# PRM_DEVICE register map
Vendor: Texas Instruments
Peripheral module from a debugger description file (folder am437x).
Registers are 32-bit, access per field, no defined reset value unless marked. A register's access mark holds for its fields unless they carry their own. Offsets are as the file gives them; lines under a group give offsets from that group; [hi:lo] are bit positions; {n}, {i} and the like mark numbered series; 'fields as' and 'values as' point back to an identical list; <NAME> marks a mode.

## PRM_DEVICE
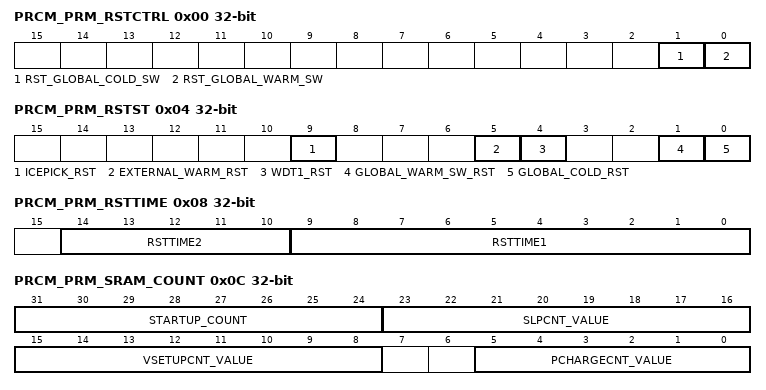
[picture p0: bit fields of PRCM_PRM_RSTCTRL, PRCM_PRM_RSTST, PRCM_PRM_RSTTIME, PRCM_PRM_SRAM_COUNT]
0x00 PRCM_PRM_RSTCTRL — Global software cold and warm reset control. This register is auto-cleared. Only write 1 is possible. A read returns 0 only.
  [1] RST_GLOBAL_COLD_SW rw — Global COLD software reset control. [[br]]This bit is reset only upon a global cold source of reset.
    1=en_2_0x1 (0X1 : Asserts a global COLD software reset. The software must ensure the SDRAM is properly put in sef-refresh mode before applying this reset.); 0=en_1_0x0 (0X0 : Global COLD software reset is cleared.)
  [0] RST_GLOBAL_WARM_SW rw — Global WARM software reset control. [[br]]This bit is reset upon any global source of reset (warm and cold).
    1=en_2_0x1 (0X1 : Asserts a global warm software reset.); 0=en_1_0x0 (0X0 : Global warm software reset is cleared.)
0x04 PRCM_PRM_RSTST — This register logs the global reset sources. Each bit is set upon release of the domain reset signal. Must be cleared by software. [warm reset insensitive]
  [9] ICEPICK_RST rw — IcePick reset event. [[br]]This is a source of global warm reset initiated by the emulation. [[br]][warm reset insensitive]
    1=en_2_0x1 (0X1 : IcePick reset has occurred.); 0=en_1_0x0 (0X0 : No ICEPICK reset.)
  [5] EXTERNAL_WARM_RST rw — External warm reset event [warm reset insensitive]
    1=en_2_0x1 (0X1 : Global external warm reset has occurred.); 0=en_1_0x0 (0X0 : No global warm reset.)
  [4] WDT1_RST rw — Watchdog1 timer reset event. [[br]]This is a source of global WARM reset. [[br]][warm reset insensitive]
    1=en_2_0x1 (0X1 : watchdog reset has occurred.); 0=en_1_0x0 (0X0 : No watchdog reset.)
  [1] GLOBAL_WARM_SW_RST rw — Global warm software reset event [warm reset insensitive]
    1=en_2_0x1 (0X1 : Global warm SW reset has occurred.); 0=en_1_0x0 (0X0 : No global warm SW reset)
  [0] GLOBAL_COLD_RST rw — Power-on (cold) reset event [warm reset insensitive]
    1=en_2_0x1 (0X1 : Power-on reset has occurred.); 0=en_1_0x0 (0X0 : No power-on reset.)
0x08 PRCM_PRM_RSTTIME — Reset duration control. [warm reset insensitive]
  [14:10] RSTTIME2 rw — (Power domain) reset duration 2 (number of RM.SYSCLK clock cycles)
  [9:0] RSTTIME1 rw — (Global) reset duration 1 (number of SYS_CLK clock cycles)
0x0C PRCM_PRM_SRAM_COUNT — Common setup for SRAM LDO transition counters. Applies to all voltage domains. [warm reset insensitive]
  [31:24] STARTUP_COUNT rw — Determines the start-up duration of SRAM and ABB LDO. [[br]]The duration is computed as 16 x NbCycles of system clock cycles. [[br]]Target is 50us.
  [23:16] SLPCNT_VALUE rw — Delay between retention/off assertion of last SRAM bank and SRAMALLRET signal to LDO is driven high. [[br]]Counting on system clock. [[br]]Target is 2us.
  [15:8] VSETUPCNT_VALUE rw — SRAM LDO rampup time from retention to active mode. [[br]]The duration is computed as 8 x NbCycles of system clock cycles. [[br]]Target is 30us.
  [5:0] PCHARGECNT_VALUE rw — Delay between de-assertion of standby_rta_ret_on and standby_rta_ret_good. [[br]]Counting on system clock. [[br]]Target is 600ns.
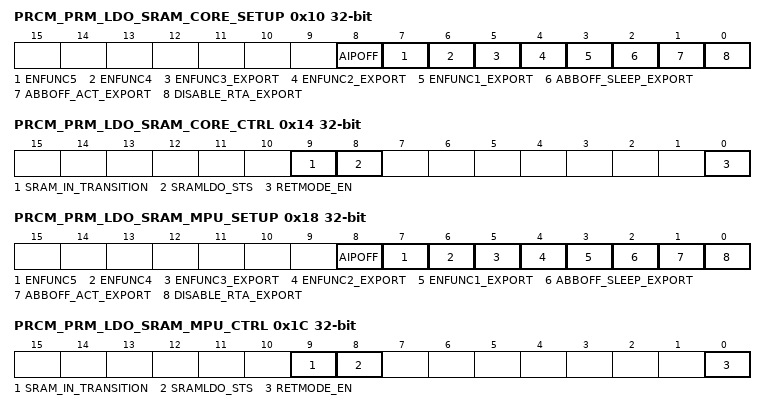
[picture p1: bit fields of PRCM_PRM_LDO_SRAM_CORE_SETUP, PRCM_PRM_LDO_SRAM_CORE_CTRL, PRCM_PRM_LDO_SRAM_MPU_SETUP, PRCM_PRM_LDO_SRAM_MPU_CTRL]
0x10 PRCM_PRM_LDO_SRAM_CORE_SETUP — Setup of the SRAM LDO for CORE voltage domain. [warm reset insensitive]
  [8] AIPOFF rw — Override on AIPOFF input of SRAM LDO.
    1=en_2_0x1 (AIPOFF signal is overriden to '1'. Corresponding SRAM LDO is disabled and in HZ mode.); 0=en_1_0x0 (AIPOFF signal is not overriden)
  [7] ENFUNC5 rw — ENFUNC5 input of SRAM LDO.
    1=en_2_0x1 (Active to retention is a two steps transfer); 0=en_1_0x0 (Active to retention is a one step transfer)
  [6] ENFUNC4 rw — ENFUNC4 input of SRAM LDO.
    1=en_2_0x1 (No external clock is supplied); 0=en_1_0x0 (One external clock is supplied)
  [5] ENFUNC3_EXPORT rw — ENFUNC3 input of SRAM LDO. [[br]]After PowerOn reset and Efuse sensing, this bitfield is automatically loaded with an Efuse value from control module. [[br]]Bitfield remains writable after this.
    1=en_2_0x1 (Sub regulation is enabled); 0=en_1_0x0 (Sub regulation is disabled)
  [4] ENFUNC2_EXPORT rw — ENFUNC2 input of SRAM LDO. [[br]]After PowerOn reset and Efuse sensing, this bitfield is automatically loaded with an Efuse value from control module. [[br]]Bitfield remains writable after this.
    1=en_2_0x1 (External cap is not used); 0=en_1_0x0 (External cap is used)
  [3] ENFUNC1_EXPORT rw — ENFUNC1 input of SRAM LDO. [[br]]After PowerOn reset and Efuse sensing, this bitfield is automatically loaded with an Efuse value from control module. [[br]]Bitfield remains writable after this.
    1=en_2_0x1 (Short circuit protection is enabled); 0=en_1_0x0 (Short circuit protection is disabled)
  [2] ABBOFF_SLEEP_EXPORT rw — Determines whether SRAMNWA is supplied by VDDS or VDDAR during deep-sleep. [[br]]After PowerOn reset and Efuse sensing, this bitfield is automatically loaded with an Efuse value from control module. [[br]]Bitfield remains writable after this.
    1=en_2_0x1 (SRAMNWA supplied with VDDAR); 0=en_1_0x0 (SRAMNWA supplied with VDDS)
  [1] ABBOFF_ACT_EXPORT rw — Determines whether SRAMNWA is supplied by VDDS or VDDAR during active mode. [[br]]After PowerOn reset and Efuse sensing, this bitfield is automatically loaded with an Efuse value from control module. [[br]]Bitfield remains writable after this.
    values as ABBOFF_SLEEP_EXPORT
  [0] DISABLE_RTA_EXPORT rw — Control for HD memory RTA feature. [[br]]After PowerOn reset and Efuse sensing, this bitfield is automatically loaded with an Efuse value from control module. [[br]]Bitfield remains writable after this. [[br]]Note : This feature is not used.
    1=en_2_0x1 (HD memory RTA feature is disabled); 0=en_1_0x0 (HD memory RTA feature is enabled)
0x14 PRCM_PRM_LDO_SRAM_CORE_CTRL — Control and status of the SRAM LDO for CORE voltage domain. [warm reset insensitive]
  [9] SRAM_IN_TRANSITION ro — Status indicating SRAM LDO state machine state.
    1=en_2_0x1 (SRAM LDO state machine is in transition state); 0=en_1_0x0 (SRAM LDO state machine is stable)
  [8] SRAMLDO_STS ro — SRAMLDO status
    1=en_2_0x1 (SRAMLDO is on RETENTION mode.); 0=en_1_0x0 (SRAMLDO is in ACTIVE mode.)
  [0] RETMODE_EN rw — Control if the SRAM LDO retention mode is used or not.
    1=en_2_0x1 (SRAM LDO go to RET mode when all memory of voltage domain are OFF or RET); 0=en_1_0x0 (SRAM LDO is not allowed to go to RET mode)
0x18 PRCM_PRM_LDO_SRAM_MPU_SETUP — Setup of the SRAM LDO for MPU voltage domain. [warm reset insensitive]
  [8] AIPOFF rw — Override on AIPOFF input of SRAM LDO.
    values as PRCM_PRM_LDO_SRAM_CORE_SETUP.AIPOFF
  [7] ENFUNC5 rw — ENFUNC5 input of SRAM LDO.
    values as PRCM_PRM_LDO_SRAM_CORE_SETUP.ENFUNC5
  [6] ENFUNC4 rw — ENFUNC4 input of SRAM LDO.
    values as PRCM_PRM_LDO_SRAM_CORE_SETUP.ENFUNC4
  [5] ENFUNC3_EXPORT rw — ENFUNC3 input of SRAM LDO. [[br]]After PowerOn reset and Efuse sensing, this bitfield is automatically loaded with an Efuse value from control module. [[br]]Bitfield remains writable after this.
    values as PRCM_PRM_LDO_SRAM_CORE_SETUP.ENFUNC3_EXPORT
  [4] ENFUNC2_EXPORT rw — ENFUNC2 input of SRAM LDO. [[br]]After PowerOn reset and Efuse sensing, this bitfield is automatically loaded with an Efuse value from control module. [[br]]Bitfield remains writable after this.
    values as PRCM_PRM_LDO_SRAM_CORE_SETUP.ENFUNC2_EXPORT
  [3] ENFUNC1_EXPORT rw — ENFUNC1 input of SRAM LDO. [[br]]After PowerOn reset and Efuse sensing, this bitfield is automatically loaded with an Efuse value from control module. [[br]]Bitfield remains writable after this.
    values as PRCM_PRM_LDO_SRAM_CORE_SETUP.ENFUNC1_EXPORT
  [2] ABBOFF_SLEEP_EXPORT rw — Determines whether SRAMNWA is supplied by VDDS or VDDAR during deep-sleep. [[br]]After PowerOn reset and Efuse sensing, this bitfield is automatically loaded with an Efuse value from control module. [[br]]Bitfield remains writable after this.
    values as PRCM_PRM_LDO_SRAM_CORE_SETUP.ABBOFF_SLEEP_EXPORT
  [1] ABBOFF_ACT_EXPORT rw — Determines whether SRAMNWA is supplied by VDDS or VDDAR during active mode. [[br]]After PowerOn reset and Efuse sensing, this bitfield is automatically loaded with an Efuse value from control module. [[br]]Bitfield remains writable after this.
    values as PRCM_PRM_LDO_SRAM_CORE_SETUP.ABBOFF_SLEEP_EXPORT
  [0] DISABLE_RTA_EXPORT rw — Control for HD memory RTA feature. [[br]]After PowerOn reset and Efuse sensing, this bitfield is automatically loaded with an Efuse value from control module. [[br]]Bitfield remains writable after this.
    values as PRCM_PRM_LDO_SRAM_CORE_SETUP.DISABLE_RTA_EXPORT
0x1C PRCM_PRM_LDO_SRAM_MPU_CTRL — Control and status of the SRAM LDO for MPU voltage domain. [warm reset insensitive]
  fields as PRCM_PRM_LDO_SRAM_CORE_CTRL
0x20 PRCM_PRM_IO_COUNT — This register allows controlling EMIF IO isolation removal setup. [warm reset insensitive]
  [7:0] ISO_2_ON_TIME rw — Determines the setup time of the DDR IOs going out of isolation. [[br]]Counting on the system clock. [[br]]Target is 1.5us.
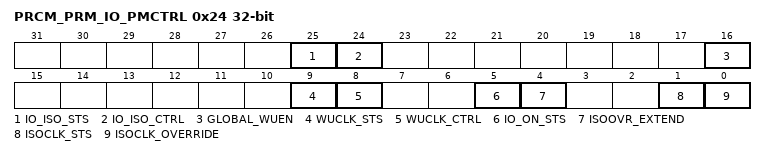
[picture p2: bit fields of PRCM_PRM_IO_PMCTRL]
0x24 PRCM_PRM_IO_PMCTRL — This register allows controlling power management features of the IOs.
  [25] IO_ISO_STS ro — IO ISO Status.
    1=en_2_0x1 (IO isolation active); 0=en_1_0x0 (IO isolation not active.)
  [24] IO_ISO_CTRL rw — IO ISO control. [[br]]writing this bit to '1' will kick off IO isolation.
    1=en_2_0x1 (Turn ON the IO isolation); 0=en_1_0x0 (Turn off the IO isolation.)
  [16] GLOBAL_WUEN rw — Global IO wakeup enable. [[br]]This is a gating condition to all individual IO WUEN coming from control module. [[br]]Gating is done in the Spinner logic.
    1=en_2_0x1 (All individual IO WUEN from control module are going to IOs.); 0=en_1_0x0 (All individual IO WUEN are gated in the Spinner logic (overriden to 0).)
  [9] WUCLK_STS ro — Gives value of WUCLKOUT signal coming back from IO pad ring.
  [8] WUCLK_CTRL rw — Direct control on WUCLKIN signal to IO pad ring.
    1=en_2_0x1 (WUCLKIN signal is driven to 1. IO wakeup daisy chain is reset and is latching current pad states and WUEN inputs.); 0=en_1_0x0 (WUCLKIN signal is driven to 0. IO wakeup daisy chain is functional as well as IO whose wakeup feature is enabled.)
  [5] IO_ON_STS ro — Gives the functional status of the IO ring.
    1=en_2_0x1 (All IOs are in the ON state.); 0=en_1_0x0 (Part or all of the IOs are not in the ON state, that is are in isolation state.)
  [4] ISOOVR_EXTEND rw — Control non-EMIF IO isolation extension.
    1=en_2_0x1 (Non-EMIF IO isolation is extended. "EMIF_ON" IO transition is stalled.); 0=en_1_0x0 (Non-EMIF IO isolation is not extended. "EMIF_ON" IO transition happens as soon as automatic restore is completed.)
  [1] ISOCLK_STS ro — Gives value of ISOCLKOUT signal coming back from IO pad ring.
  [0] ISOCLK_OVERRIDE rw — Override control on ISOCLKIN signal to IO pad ring.When not overriden, this signal is controlled by hardware only.
    1=en_2_0x1 (ISOCLKIN signal is overriden to active value ('1').); 0=en_1_0x0 (ISOCLKIN signal is not overriden.)
0x28 PRCM_PRM_VC_VAL_BYPASS — This MMR has flag to indicate OPP change to EMIF to allow read/write leveling.
  [25] OPP_CHANGE_EMIF_LVL rw — This bit controls read-write leveling of EMIF memories (DDR3). [[br]]It must be set in case OPP voltage change is done.
    1=en_2_0x1 (disable leveling); 0=en_1_0x0 (Enable leveling)
0x30 PRCM_PRM_EMIF_CTRL — This register controls EMIF controller low power configurations.
  [0] EMIF_DEVOFF rw — EMIF Controller DeepSleep Mode Enable. [[br]]This bit should be programmed to '1' (ON) before going into DeepSleep. [[br]]Must be cleared to '0' (OFF) after wakeup and EMIF configuration is completed.
    1=en_2_0x1 (EMIF Controller DeepSleep Mode is Enabled.); 0=en_1_0x0 (EMIF Controller DeepSleep Mode is Disabled.)
